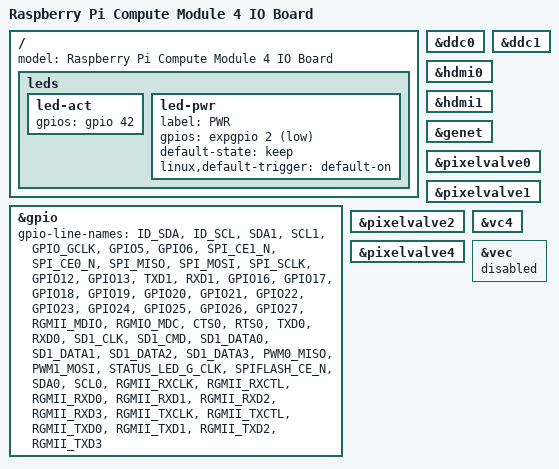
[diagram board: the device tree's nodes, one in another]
// SPDX-License-Identifier: GPL-2.0
/dts-v1/;
#include "bcm2711-rpi-cm4.dtsi"
#include "bcm283x-rpi-usb-host.dtsi"

/ {
	model = "Raspberry Pi Compute Module 4 IO Board";

	leds {
		led-act {
			gpios = <&gpio 42 GPIO_ACTIVE_HIGH>;
		};

		led-pwr {
			label = "PWR";
			gpios = <&expgpio 2 GPIO_ACTIVE_LOW>;
			default-state = "keep";
			linux,default-trigger = "default-on";
		};
	};
};

&ddc0 {
	status = "okay";
};

&ddc1 {
	status = "okay";
};

&gpio {
	/*
	 * Parts taken from rpi_SCH_4b_4p0_reduced.pdf and
	 * the official GPU firmware DT blob.
	 *
	 * Legend:
	 * "FOO" = GPIO line named "FOO" on the schematic
	 * "FOO_N" = GPIO line named "FOO" on schematic, active low
	 */
	gpio-line-names = "ID_SDA",
			  "ID_SCL",
			  "SDA1",
			  "SCL1",
			  "GPIO_GCLK",
			  "GPIO5",
			  "GPIO6",
			  "SPI_CE1_N",
			  "SPI_CE0_N",
			  "SPI_MISO",
			  "SPI_MOSI",
			  "SPI_SCLK",
			  "GPIO12",
			  "GPIO13",
			  /* Serial port */
			  "TXD1",
			  "RXD1",
			  "GPIO16",
			  "GPIO17",
			  "GPIO18",
			  "GPIO19",
			  "GPIO20",
			  "GPIO21",
			  "GPIO22",
			  "GPIO23",
			  "GPIO24",
			  "GPIO25",
			  "GPIO26",
			  "GPIO27",
			  "RGMII_MDIO",
			  "RGMIO_MDC",
			  /* Used by BT module */
			  "CTS0",
			  "RTS0",
			  "TXD0",
			  "RXD0",
			  /* Used by Wifi */
			  "SD1_CLK",
			  "SD1_CMD",
			  "SD1_DATA0",
			  "SD1_DATA1",
			  "SD1_DATA2",
			  "SD1_DATA3",
			  /* Shared with SPI flash */
			  "PWM0_MISO",
			  "PWM1_MOSI",
			  "STATUS_LED_G_CLK",
			  "SPIFLASH_CE_N",
			  "SDA0",
			  "SCL0",
			  "RGMII_RXCLK",
			  "RGMII_RXCTL",
			  "RGMII_RXD0",
			  "RGMII_RXD1",
			  "RGMII_RXD2",
			  "RGMII_RXD3",
			  "RGMII_TXCLK",
			  "RGMII_TXCTL",
			  "RGMII_TXD0",
			  "RGMII_TXD1",
			  "RGMII_TXD2",
			  "RGMII_TXD3";
};

&hdmi0 {
	status = "okay";
};

&hdmi1 {
	status = "okay";
};

&genet {
	status = "okay";
};

&pixelvalve0 {
	status = "okay";
};

&pixelvalve1 {
	status = "okay";
};

&pixelvalve2 {
	status = "okay";
};

&pixelvalve4 {
	status = "okay";
};

&vc4 {
	status = "okay";
};

&vec {
	status = "disabled";
};
